# MIMXRT1052 register map
Vendor: nxp.com; File version: 1.0
CPU: CM7 r0p1, little endian, MPU, FPU, VTOR, 4 interrupt priority bits
Registers are 32-bit, read-write, reset 0x0 unless marked. A register's access mark holds for its fields unless they carry their own. Offsets are from the block's base; [hi:lo] are bit positions; {n}, {i} and the like mark numbered series; 'fields as' and 'values as' point back to an identical list.

## TMR1 — Quad Timer
Base 0x401DC000; register names take the prefix TMR1_
Same registers: TMR2 0x401E0000 (register names take the prefix TMR2_), TMR3 0x401E4000 (register names take the prefix TMR3_), TMR4 0x401E8000 (register names take the prefix TMR4_)
{0x0+0x20*i} COMP1{i} (i=0..3) 16-bit — Timer Channel Compare Register 1
  [15:0] COMPARISON_1 — Comparison Value 1
{0x2+0x20*i} COMP2{i} (i=0..3) 16-bit — Timer Channel Compare Register 2
  [15:0] COMPARISON_2 — Comparison Value 2
{0x4+0x20*i} CAPT{i} (i=0..3) 16-bit — Timer Channel Capture Register
  [15:0] CAPTURE — Capture Value
{0x6+0x20*i} LOAD{i} (i=0..3) 16-bit — Timer Channel Load Register
  [15:0] LOAD — Timer Load Register
{0x8+0x20*i} HOLD{i} (i=0..3) 16-bit — Timer Channel Hold Register
  [15:0] HOLD — This read/write register stores the counter's values of specific channels whenever any of the four counters within a module is read
{0xA+0x20*i} CNTR{i} (i=0..3) 16-bit — Timer Channel Counter Register
  [15:0] COUNTER — This read/write register is the counter for the corresponding channel in a timer module.
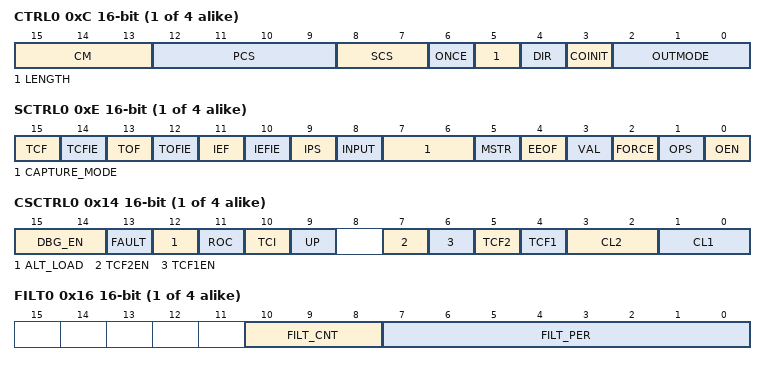
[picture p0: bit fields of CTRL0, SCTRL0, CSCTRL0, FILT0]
{0xC+0x20*i} CTRL{i} (i=0..3) 16-bit — Timer Channel Control Register
  [15:13] CM — Count Mode
    0=No operation; 1=Count rising edges of primary sourceRising edges are counted only when SCTRL[IPS] = 0. Falling edges are counted when SCTRL[IPS] = 1. If the primary count source is IP bus clock divide by 1, only rising edges are counted regardless of the value of SCTRL[IPS].; 2=Count rising and falling edges of primary sourceIP bus clock divide by 1 cannot be used as a primary count source in edge count mode; 3=Count rising edges of primary source while secondary input high active; 4=Quadrature count mode, uses primary and secondary sources; 5=Count rising edges of primary source; secondary source specifies directionRising edges are counted only when SCTRL[IPS] = 0. Falling edges are counted when SCTRL[IPS] = 1.; 6=Edge of secondary source triggers primary count until compare; 7=Cascaded counter mode (up/down)The primary count source must be set to one of the counter outputs
  [12:9] PCS — Primary Count Source
    {v}=Counter {v} input pin (v=0..3); {v}=Counter {v-4} output (v=4..7); 8=IP bus clock divide by 1 prescaler; 9=IP bus clock divide by 2 prescaler; 10=IP bus clock divide by 4 prescaler; 11=IP bus clock divide by 8 prescaler; 12=IP bus clock divide by 16 prescaler; 13=IP bus clock divide by 32 prescaler; 14=IP bus clock divide by 64 prescaler; 15=IP bus clock divide by 128 prescaler
  [8:7] SCS — Secondary Count Source
    {v}=Counter {v} input pin (v=0..3)
  [6] ONCE — Count Once
    0=Count repeatedly; 1=Count until compare and then stop. If counting up, a successful compare occurs when the counter reaches a COMP1 value. If counting down, a successful compare occurs when the counter reaches a COMP2 value. When output mode $4 is used, the counter re-initializes after reaching the COMP1 value, continues to count to the COMP2 value, and then stops.
  [5] LENGTH — Count Length
    0=Count until roll over at $FFFF and continue from $0000; 1=Count until compare, then re-initialize. If counting up, a successful compare occurs when the counter reaches a COMP1 value. If counting down, a successful compare occurs when the counter reaches a COMP2 value. When output mode $4 is used, alternating values of COMP1 and COMP2 are used to generate successful comparisons. For example, the counter counts until a COMP1 value is reached, re-initializes, counts until COMP2 value is reached, re-initializes, counts until COMP1 value is reached, and so on.
  [4] DIR — Count Direction
    0=Count up; 1=Count down
  [3] COINIT — Co-Channel Initialization
    0=Co-channel counter/timers cannot force a re-initialization of this counter/timer; 1=Co-channel counter/timers may force a re-initialization of this counter/timer
  [2:0] OUTMODE — Output Mode
    0=Asserted while counter is active; 1=Clear OFLAG output on successful compare; 2=Set OFLAG output on successful compare; 3=Toggle OFLAG output on successful compare; 4=Toggle OFLAG output using alternating compare registers; 5=Set on compare, cleared on secondary source input edge; 6=Set on compare, cleared on counter rollover; 7=Enable gated clock output while counter is active
{0xE+0x20*i} SCTRL{i} (i=0..3) 16-bit — Timer Channel Status and Control Register
  [15] TCF — Timer Compare Flag
  [14] TCFIE — Timer Compare Flag Interrupt Enable
  [13] TOF — Timer Overflow Flag
  [12] TOFIE — Timer Overflow Flag Interrupt Enable
  [11] IEF — Input Edge Flag
  [10] IEFIE — Input Edge Flag Interrupt Enable
  [9] IPS — Input Polarity Select
  [8] INPUT ro — External Input Signal
  [7:6] CAPTURE_MODE — Input Capture Mode
    0=Capture function is disabled; 1=Load capture register on rising edge (when IPS=0) or falling edge (when IPS=1) of input; 2=Load capture register on falling edge (when IPS=0) or rising edge (when IPS=1) of input; 3=Load capture register on both edges of input
  [5] MSTR — Master Mode
  [4] EEOF — Enable External OFLAG Force
  [3] VAL — Forced OFLAG Value
  [2] FORCE — Force OFLAG Output
  [1] OPS — Output Polarity Select
    0=True polarity; 1=Inverted polarity
  [0] OEN — Output Enable
    0=The external pin is configured as an input; 1=The OFLAG output signal is driven on the external pin. Other timer groups using this external pin as their input see the driven value. The polarity of the signal is determined by OPS.
{0x10+0x20*i} CMPLD1{i} (i=0..3) 16-bit — Timer Channel Comparator Load Register 1
  [15:0] COMPARATOR_LOAD_1 — This read/write register is the comparator 1 preload value for the COMP1 register for the corresponding channel in a timer module
{0x12+0x20*i} CMPLD2{i} (i=0..3) 16-bit — Timer Channel Comparator Load Register 2
  [15:0] COMPARATOR_LOAD_2 — This read/write register is the comparator 2 preload value for the COMP2 register for the corresponding channel in a timer module
{0x14+0x20*i} CSCTRL{i} (i=0..3) 16-bit — Timer Channel Comparator Status and Control Register
  [15:14] DBG_EN — Debug Actions Enable
    0=Continue with normal operation during debug mode. (default); 1=Halt TMR counter during debug mode; 2=Force TMR output to logic 0 (prior to consideration of SCTRL[OPS]); 3=Both halt counter and force output to 0 during debug mode
  [13] FAULT — Fault Enable
    0=Fault function disabled; 1=Fault function enabled
  [12] ALT_LOAD — Alternative Load Enable
    0=Counter can be re-initialized only with the LOAD register; 1=Counter can be re-initialized with the LOAD or CMPLD2 registers depending on count direction
  [11] ROC — Reload on Capture
    0=Do not reload the counter on a capture event; 1=Reload the counter on a capture event
  [10] TCI — Triggered Count Initialization Control
    0=Stop counter upon receiving a second trigger event while still counting from the first trigger event; 1=Reload the counter upon receiving a second trigger event while still counting from the first trigger event
  [9] UP ro — Counting Direction Indicator
    0=The last count was in the DOWN direction; 1=The last count was in the UP direction
  [7] TCF2EN — Timer Compare 2 Interrupt Enable
  [6] TCF1EN — Timer Compare 1 Interrupt Enable
  [5] TCF2 — Timer Compare 2 Interrupt Flag
  [4] TCF1 — Timer Compare 1 Interrupt Flag
  [3:2] CL2 — Compare Load Control 2
    0=Never preload; 1=Load upon successful compare with the value in COMP1; 2=Load upon successful compare with the value in COMP2
  [1:0] CL1 — Compare Load Control 1
    values as CL2
{0x16+0x20*i} FILT{i} (i=0..3) 16-bit — Timer Channel Input Filter Register
  [10:8] FILT_CNT — Input Filter Sample Count
  [7:0] FILT_PER — Input Filter Sample Period
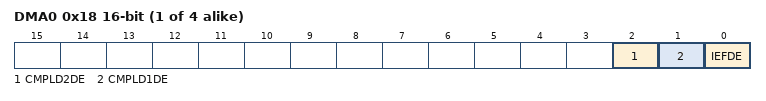
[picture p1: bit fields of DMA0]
{0x18+0x20*i} DMA{i} (i=0..3) 16-bit — Timer Channel DMA Enable Register
  [2] CMPLD2DE — Comparator Preload Register 2 DMA Enable
  [1] CMPLD1DE — Comparator Preload Register 1 DMA Enable
  [0] IEFDE — Input Edge Flag DMA Enable
0x1E ENBL 16-bit reset 0xF — Timer Channel Enable Register
  [3:0] ENBL — Timer Channel Enable
    0=Timer channel is disabled; 1=Timer channel is enabled. (default)
